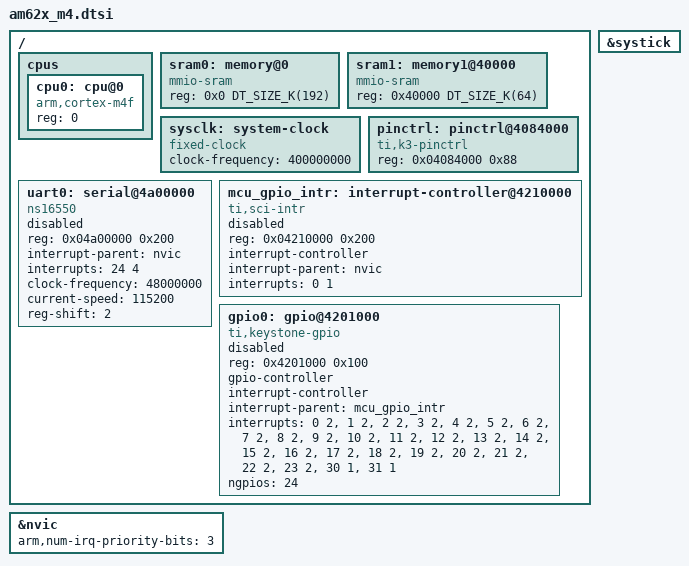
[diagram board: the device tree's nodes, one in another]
/*
 * Copyright (c) 2023 Texas Instruments Incorporated
 *
 * SPDX-License-Identifier: Apache-2.0
 */

#include <mem.h>
#include <freq.h>
#include <arm/armv7-m.dtsi>
#include <zephyr/dt-bindings/pinctrl/ti-k3-pinctrl.h>
#include <zephyr/dt-bindings/gpio/gpio.h>

/ {

	cpus {
		#address-cells = <1>;
		#size-cells = <0>;

		cpu0: cpu@0 {
			device_type = "cpu";
			compatible = "arm,cortex-m4f";
			reg = <0>;
		};
	};

	sram0: memory@0 {
		compatible = "mmio-sram";
		reg = <0x0 DT_SIZE_K(192)>;		/* 192 KB of SRAM (I-Code) */
	};

	sram1: memory1@40000 {
		compatible = "mmio-sram";
		reg = <0x40000 DT_SIZE_K(64)>;		/* 64 KB of SRAM (D-Code) */
	};

	sysclk: system-clock {
		compatible = "fixed-clock";
		clock-frequency = <400000000>;
		#clock-cells = <0>;
	};

	pinctrl: pinctrl@4084000 {
		compatible = "ti,k3-pinctrl";
		reg = <0x04084000 0x88>;
		status = "okay";
	};

	uart0: serial@4a00000 {
		compatible = "ns16550";
		reg = <0x04a00000 0x200>;
		interrupt-parent = <&nvic>;
		interrupts = <24 4>;
		clock-frequency = <48000000>;
		current-speed = <115200>;
		reg-shift = <2>;
		status = "disabled";
	};

	mcu_gpio_intr: interrupt-controller@4210000 {
		compatible = "ti,sci-intr";
		reg = <0x04210000 0x200>;
		#address-cells = <2>;
		interrupt-controller;
		interrupt-parent = <&nvic>;
		interrupts = <0 1>;
		#interrupt-cells = <2>;
		status = "disabled";
	};

	gpio0: gpio@4201000 {
		compatible = "ti,keystone-gpio";
		reg = <0x4201000 0x100>;
		#address-cells = <2>;
		gpio-controller;
		#gpio-cells = <2>;
		interrupt-controller;
		interrupt-parent = <&mcu_gpio_intr>;
		interrupts = <0 2>, <1 2>, <2 2>, <3 2>,
			     <4 2>, <5 2>, <6 2>, <7 2>,
			     <8 2>, <9 2>, <10 2>, <11 2>,
			     <12 2>, <13 2>, <14 2>, <15 2>,
			     <16 2>, <17 2>, <18 2>, <19 2>,
			     <20 2>, <21 2>, <22 2>, <23 2>,
			     <30 1>, <31 1>;
		#interrupt-cells = <2>;
		ngpios = <24>;
		status = "disabled";
	};
};

&nvic {
	arm,num-irq-priority-bits = <3>;
};

&systick {
	status = "okay";
};
